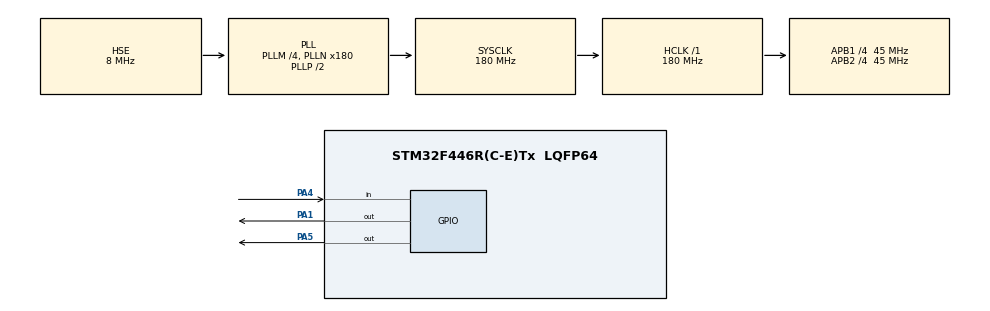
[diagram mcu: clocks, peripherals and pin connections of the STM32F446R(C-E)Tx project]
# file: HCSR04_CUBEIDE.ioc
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Mcu.Family=STM32F4
Mcu.Name=STM32F446R(C-E)Tx
Mcu.Package=LQFP64
NVIC.PriorityGroup=NVIC_PRIORITYGROUP_4
PA1.Signal=GPIO_Output
PA4.Signal=GPIO_Input
PA5.Signal=GPIO_Output
PH0-OSC_IN.Mode=HSE-External-Oscillator
PH0-OSC_IN.Signal=RCC_OSC_IN
PH1-OSC_OUT.Mode=HSE-External-Oscillator
PH1-OSC_OUT.Signal=RCC_OSC_OUT
ProjectManager.HeapSize=0x200
ProjectManager.StackSize=0x400
ProjectManager.TargetToolchain=STM32CubeIDE
RCC.AHBFreq_Value=180000000
RCC.APB1CLKDivider=RCC_HCLK_DIV4
RCC.APB1Freq_Value=45000000
RCC.APB1TimFreq_Value=90000000
RCC.APB2CLKDivider=RCC_HCLK_DIV4
RCC.APB2Freq_Value=45000000
RCC.APB2TimFreq_Value=90000000
RCC.CortexFreq_Value=180000000
RCC.HCLKFreq_Value=180000000
RCC.HSE_VALUE=8000000
RCC.PLLM=4
RCC.PLLN=180
RCC.PLLSourceVirtual=RCC_PLLSOURCE_HSE
RCC.SYSCLKFreq_VALUE=180000000
RCC.SYSCLKSource=RCC_SYSCLKSOURCE_PLLCLK
RCC.USBFreq_Value=180000000
RCC.VCOOutputFreq_Value=360000000
TIM1.Period=0xffff-1
TIM1.Prescaler=90-1
VP_TIM1_VS_ClockSourceINT.Mode=Internal
board=custom

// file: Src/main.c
/* USER CODE BEGIN Header */
/**
  ******************************************************************************
  * @file           : main.c
  * @brief          : Main program body
  ******************************************************************************
  * @attention
  *
  * <h2><center>&copy; Copyright (c) 2019 STMicroelectronics.
  * All rights reserved.</center></h2>
  *
  * This software component is licensed by ST under BSD 3-Clause license,
  * the "License"; You may not use this file except in compliance with the
  * License. You may obtain a copy of the License at:
  *                        opensource.org/licenses/BSD-3-Clause
  *
  ******************************************************************************
  */
/* USER CODE END Header */

#include "main.h"

TIM_HandleTypeDef htim1;

void SystemClock_Config(void);
static void MX_GPIO_Init(void);
static void MX_TIM1_Init(void);

/* USER CODE BEGIN 0 */

void delay (uint32_t us)
{
	__HAL_TIM_SET_COUNTER(&htim1, 0);
	while ((__HAL_TIM_GET_COUNTER(&htim1))<us);
}

uint32_t local_time, sensor_time;
uint32_t distance;

uint32_t hcsr04_read (void)
{
	local_time=0;
	HAL_GPIO_WritePin(GPIOA, GPIO_PIN_1, GPIO_PIN_RESET);  // pull the TRIG pin HIGH
	delay(2);  // wait for 2 us

	HAL_GPIO_WritePin(GPIOA, GPIO_PIN_1, GPIO_PIN_SET);  // pull the TRIG pin HIGH
	delay(10);  // wait for 10 us
	HAL_GPIO_WritePin(GPIOA, GPIO_PIN_1, GPIO_PIN_RESET);  // pull the TRIG pin low

	// read the time for which the pin is high

	while (!(HAL_GPIO_ReadPin(GPIOA, GPIO_PIN_4)));  // wait for the ECHO pin to go high
	while (HAL_GPIO_ReadPin(GPIOA, GPIO_PIN_4))    // while the pin is high
	 {
		local_time++;   // measure time for which the pin is high
		delay (1);
	 }
	return local_time;
}

/* USER CODE END 0 */

int main(void)
{

  /* MCU Configuration--------------------------------------------------------*/

  /* Reset of all peripherals, Initializes the Flash interface and the Systick. */
  HAL_Init();

  /* Configure the system clock */
  SystemClock_Config();

  /* Initialize all configured peripherals */
  MX_GPIO_Init();
  MX_TIM1_Init();
  /* USER CODE BEGIN 2 */

  HAL_TIM_Base_Start(&htim1);

  /* USER CODE END 2 */

  /* Infinite loop */
  while (1)
  {

    /* USER CODE BEGIN 3 */
	  sensor_time = hcsr04_read();
	  distance  = sensor_time * .034/2;

	  HAL_Delay(200);
  }
  /* USER CODE END 3 */
}

void SystemClock_Config(void)
{
  RCC_OscInitTypeDef RCC_OscInitStruct = {0};
  RCC_ClkInitTypeDef RCC_ClkInitStruct = {0};

  /** Configure the main internal regulator output voltage
  */
  __HAL_RCC_PWR_CLK_ENABLE();
  __HAL_PWR_VOLTAGESCALING_CONFIG(PWR_REGULATOR_VOLTAGE_SCALE1);
  /** Initializes the CPU, AHB and APB busses clocks
  */
  RCC_OscInitStruct.OscillatorType = RCC_OSCILLATORTYPE_HSE;
  RCC_OscInitStruct.HSEState = RCC_HSE_ON;
  RCC_OscInitStruct.PLL.PLLState = RCC_PLL_ON;
  RCC_OscInitStruct.PLL.PLLSource = RCC_PLLSOURCE_HSE;
  RCC_OscInitStruct.PLL.PLLM = 4;
  RCC_OscInitStruct.PLL.PLLN = 180;
  RCC_OscInitStruct.PLL.PLLP = RCC_PLLP_DIV2;
  RCC_OscInitStruct.PLL.PLLQ = 2;
  RCC_OscInitStruct.PLL.PLLR = 2;
  if (HAL_RCC_OscConfig(&RCC_OscInitStruct) != HAL_OK)
  {
    Error_Handler();
  }
  /** Activate the Over-Drive mode
  */
  if (HAL_PWREx_EnableOverDrive() != HAL_OK)
  {
    Error_Handler();
  }
  /** Initializes the CPU, AHB and APB busses clocks
  */
  RCC_ClkInitStruct.ClockType = RCC_CLOCKTYPE_HCLK|RCC_CLOCKTYPE_SYSCLK
                              |RCC_CLOCKTYPE_PCLK1|RCC_CLOCKTYPE_PCLK2;
  RCC_ClkInitStruct.SYSCLKSource = RCC_SYSCLKSOURCE_PLLCLK;
  RCC_ClkInitStruct.AHBCLKDivider = RCC_SYSCLK_DIV1;
  RCC_ClkInitStruct.APB1CLKDivider = RCC_HCLK_DIV4;
  RCC_ClkInitStruct.APB2CLKDivider = RCC_HCLK_DIV4;

  if (HAL_RCC_ClockConfig(&RCC_ClkInitStruct, FLASH_LATENCY_5) != HAL_OK)
  {
    Error_Handler();
  }
}

static void MX_TIM1_Init(void)
{

  TIM_ClockConfigTypeDef sClockSourceConfig = {0};
  TIM_MasterConfigTypeDef sMasterConfig = {0};

  htim1.Instance = TIM1;
  htim1.Init.Prescaler = 90-1;
  htim1.Init.CounterMode = TIM_COUNTERMODE_UP;
  htim1.Init.Period = 0xffff-1;
  htim1.Init.ClockDivision = TIM_CLOCKDIVISION_DIV1;
  htim1.Init.RepetitionCounter = 0;
  htim1.Init.AutoReloadPreload = TIM_AUTORELOAD_PRELOAD_DISABLE;
  if (HAL_TIM_Base_Init(&htim1) != HAL_OK)
  {
    Error_Handler();
  }
  sClockSourceConfig.ClockSource = TIM_CLOCKSOURCE_INTERNAL;
  if (HAL_TIM_ConfigClockSource(&htim1, &sClockSourceConfig) != HAL_OK)
  {
    Error_Handler();
  }
  sMasterConfig.MasterOutputTrigger = TIM_TRGO_RESET;
  sMasterConfig.MasterSlaveMode = TIM_MASTERSLAVEMODE_DISABLE;
  if (HAL_TIMEx_MasterConfigSynchronization(&htim1, &sMasterConfig) != HAL_OK)
  {
    Error_Handler();
  }

}

static void MX_GPIO_Init(void)
{
  GPIO_InitTypeDef GPIO_InitStruct = {0};

  /* GPIO Ports Clock Enable */
  __HAL_RCC_GPIOH_CLK_ENABLE();
  __HAL_RCC_GPIOA_CLK_ENABLE();

  /*Configure GPIO pin Output Level */
  HAL_GPIO_WritePin(GPIOA, GPIO_PIN_1|GPIO_PIN_5, GPIO_PIN_RESET);

  /*Configure GPIO pins : PA1 PA5 */
  GPIO_InitStruct.Pin = GPIO_PIN_1|GPIO_PIN_5;
  GPIO_InitStruct.Mode = GPIO_MODE_OUTPUT_PP;
  GPIO_InitStruct.Pull = GPIO_NOPULL;
  GPIO_InitStruct.Speed = GPIO_SPEED_FREQ_LOW;
  HAL_GPIO_Init(GPIOA, &GPIO_InitStruct);

  /*Configure GPIO pin : PA4 */
  GPIO_InitStruct.Pin = GPIO_PIN_4;
  GPIO_InitStruct.Mode = GPIO_MODE_INPUT;
  GPIO_InitStruct.Pull = GPIO_NOPULL;
  HAL_GPIO_Init(GPIOA, &GPIO_InitStruct);

}

void Error_Handler(void)
{
}

/************************ (C) COPYRIGHT STMicroelectronics *****END OF FILE****/
